# STM32U5G9 register map
File version: 1.3
CPU: CM33 r0p1, little endian, MPU, FPU, 4 interrupt priority bits
Registers are 32-bit, read-write, reset 0x0 unless marked. A register's access mark holds for its fields unless they carry their own. Offsets are from the block's base; [hi:lo] are bit positions; {n}, {i} and the like mark numbered series.

## GPIOA — General-purpose I/Os
Base 0x42020000
Same registers: SEC_GPIOA 0x52020000
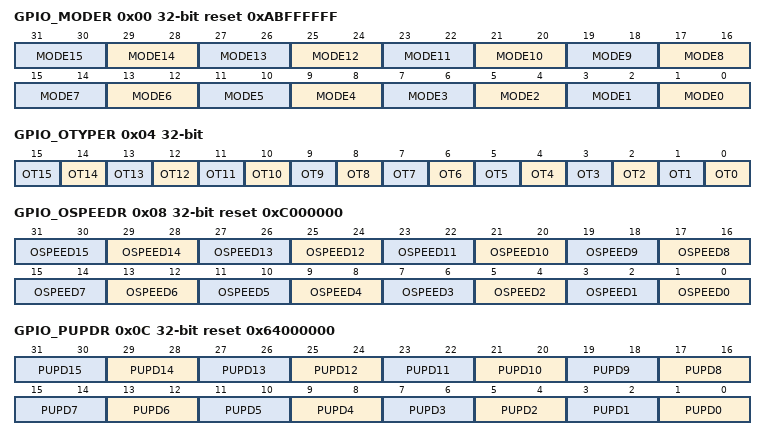
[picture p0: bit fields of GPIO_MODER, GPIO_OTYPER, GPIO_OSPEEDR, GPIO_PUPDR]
0x00 GPIO_MODER reset 0xABFFFFFF — GPIO port mode register
  [all] fields
    0=Input mode; 1=General purpose output mode; 2=Alternate function mode; 3=Analog mode (reset state)
  [2n+1:2n] MODE{n} (n=0..15) — Port x configuration I/O pin y
0x04 GPIO_OTYPER — GPIO port output type register
  [all] fields
    0=Output push-pull (reset state); 1=Output open-drain
  [n] OT{n} (n=0..15) — Port x configuration I/O pin y
0x08 GPIO_OSPEEDR reset 0xC000000 — GPIO port output speed register
  [all] fields
    0=Low speed; 1=Medium speed; 2=High speed; 3=Very-high speed
  [2n+1:2n] OSPEED{n} (n=0..15) — Port x configuration I/O pin y
0x0C GPIO_PUPDR reset 0x64000000 — GPIO port pull-up/pull-down register
  [all] fields
    0=No pull-up, pull-down; 1=Pull-up; 2=Pull-down
  [2n+1:2n] PUPD{n} (n=0..15) — Port x configuration I/O pin y
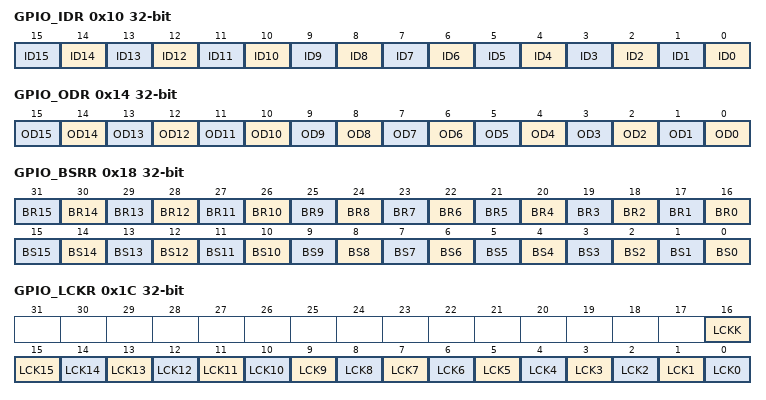
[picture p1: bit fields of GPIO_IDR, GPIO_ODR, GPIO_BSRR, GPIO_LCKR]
0x10 GPIO_IDR ro (reset mask 0xFFFF0000) — GPIO port input data register
  [n] ID{n} (n=0..15) — Port x input data I/O pin y
0x14 GPIO_ODR — GPIO port output data register
  [n] OD{n} (n=0..15) — Port output data I/O pin y
0x18 GPIO_BSRR wo — GPIO port bit set/reset register
  [n+16] BR{n} (n=0..15) — Port x reset I/O pin y
    0=No action on the corresponding ODy bit; 1=Resets the corresponding ODy bit
  [n] BS{n} (n=0..15) — Port x set I/O pin y
    0=No action on the corresponding ODy bit; 1=Sets the corresponding ODy bit
0x1C GPIO_LCKR — GPIO port configuration lock register
  [16] LCKK — Lock key
    0=Port configuration lock key not active; 1=Port configuration lock key active. The GPIOx_LCKR register is locked until the next MCU reset or peripheral reset.
  [n] LCK{n} (n=0..15) — Port x lock I/O pin y
    0=Port configuration not locked; 1=Port configuration locked
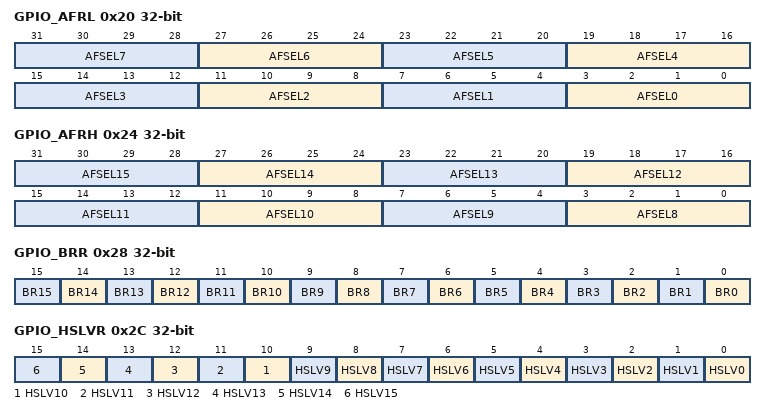
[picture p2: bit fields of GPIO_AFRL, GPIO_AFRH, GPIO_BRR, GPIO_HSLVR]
0x20 GPIO_AFRL — GPIO alternate function low register
  [all] fields
    {v}=AF{v} (v=0..15)
  [4n+3:4n] AFSEL{n} (n=0..7) — Alternate function selection for port x I/O pin y
0x24 GPIO_AFRH — GPIO alternate function high register
  [all] fields
    {v}=AF{v} (v=0..15)
  [4n-29:4n-32] AFSEL{n} (n=8..15) — Alternate function selection for port x I/O pin y
0x28 GPIO_BRR wo — GPIO port bit reset register
  [all] fields
    0=No action on the corresponding ODy bit; 1=Reset the corresponding ODy bit
  [n] BR{n} (n=0..15) — Port x reset IO pin y
0x2C GPIO_HSLVR — GPIO high-speed low-voltage register
  [all] fields
    0=I/O speed optimization disabled; 1=I/O speed optimization enabled
  [n] HSLV{n} (n=0..15) — Port x high-speed low-voltage configuration
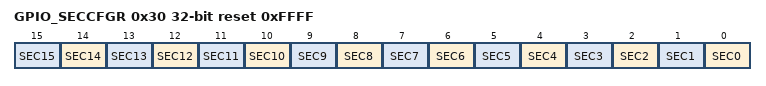
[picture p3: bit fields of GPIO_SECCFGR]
0x30 GPIO_SECCFGR reset 0xFFFF — GPIO secure configuration register
  [all] fields
    0=The I/O pin is non-secure; 1=The I/O pin is secure. Refer to Table 131 for all corresponding secured bits.
  [n] SEC{n} (n=0..15) — I/O pin of Port x secure bit enable y

## GPIOB — General-purpose I/Os
Base 0x42020400
Same registers: SEC_GPIOB 0x52020400
Registers as GPIOA; these are added or differ:
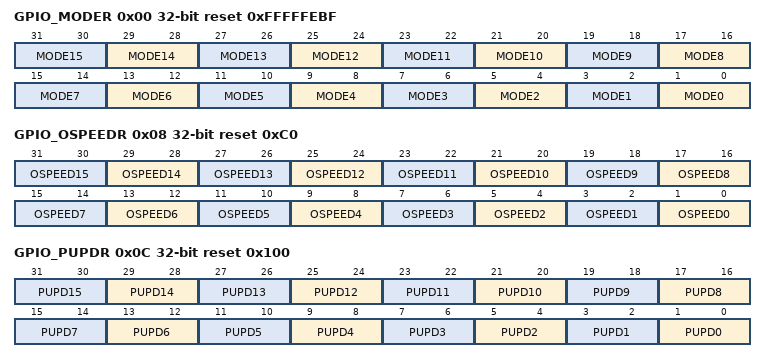
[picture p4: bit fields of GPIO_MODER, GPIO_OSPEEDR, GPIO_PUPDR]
0x00 GPIO_MODER reset 0xFFFFFEBF — GPIO port mode register
  [all] fields
    0=Input mode; 1=General purpose output mode; 2=Alternate function mode; 3=Analog mode (reset state)
  [2n+1:2n] MODE{n} (n=0..15) — Port x configuration I/O pin y
0x08 GPIO_OSPEEDR reset 0xC0 — GPIO port output speed register
  [all] fields
    0=Low speed; 1=Medium speed; 2=High speed; 3=Very-high speed
  [2n+1:2n] OSPEED{n} (n=0..15) — Port x configuration I/O pin y
0x0C GPIO_PUPDR reset 0x100 — GPIO port pull-up/pull-down register
  [all] fields
    0=No pull-up, pull-down; 1=Pull-up; 2=Pull-down
  [2n+1:2n] PUPD{n} (n=0..15) — Port x configuration I/O pin y

## GPIOC — General-purpose I/Os
Base 0x42020800
Same registers: GPIOD 0x42020C00, GPIOE 0x42021000, GPIOF 0x42021400, GPIOG 0x42021800, GPIOH 0x42021C00, GPIOI 0x42022000, GPIOJ 0x42022400, SEC_GPIOC 0x52020800, SEC_GPIOD 0x52020C00, SEC_GPIOE 0x52021000, SEC_GPIOF 0x52021400, SEC_GPIOG 0x52021800, SEC_GPIOH 0x52021C00, SEC_GPIOI 0x52022000, SEC_GPIOJ 0x52022400
Registers as GPIOA; these are added or differ:
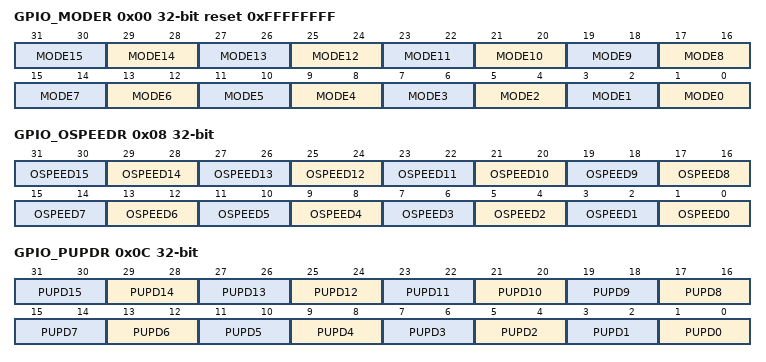
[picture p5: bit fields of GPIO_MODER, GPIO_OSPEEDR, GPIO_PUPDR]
0x00 GPIO_MODER reset 0xFFFFFFFF — GPIO port mode register
  [all] fields
    0=Input mode; 1=General purpose output mode; 2=Alternate function mode; 3=Analog mode (reset state)
  [2n+1:2n] MODE{n} (n=0..15) — Port x configuration I/O pin y
0x08 GPIO_OSPEEDR — GPIO port output speed register
  [all] fields
    0=Low speed; 1=Medium speed; 2=High speed; 3=Very-high speed
  [2n+1:2n] OSPEED{n} (n=0..15) — Port x configuration I/O pin y
0x0C GPIO_PUPDR — GPIO port pull-up/pull-down register
  [all] fields
    0=No pull-up, pull-down; 1=Pull-up; 2=Pull-down
  [2n+1:2n] PUPD{n} (n=0..15) — Port x configuration I/O pin y
